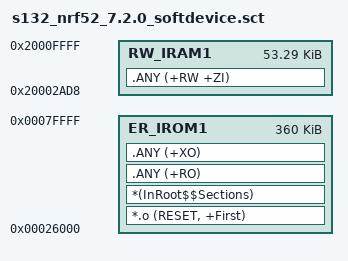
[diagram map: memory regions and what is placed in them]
; *************************************************************
; *** Scatter-Loading Description File generated by uVision ***
; *************************************************************

LR_IROM1 0x00026000 0x0005A000  {    ; load region size_region
  ER_IROM1 0x00026000 0x0005A000  {  ; load address = execution address
   *.o (RESET, +First)
   *(InRoot$$Sections)
   .ANY (+RO)
   .ANY (+XO)
  }
  RW_IRAM1 0x20002AD8 0x0000D528  {  ; RW data
   .ANY (+RW +ZI)
  }
}

